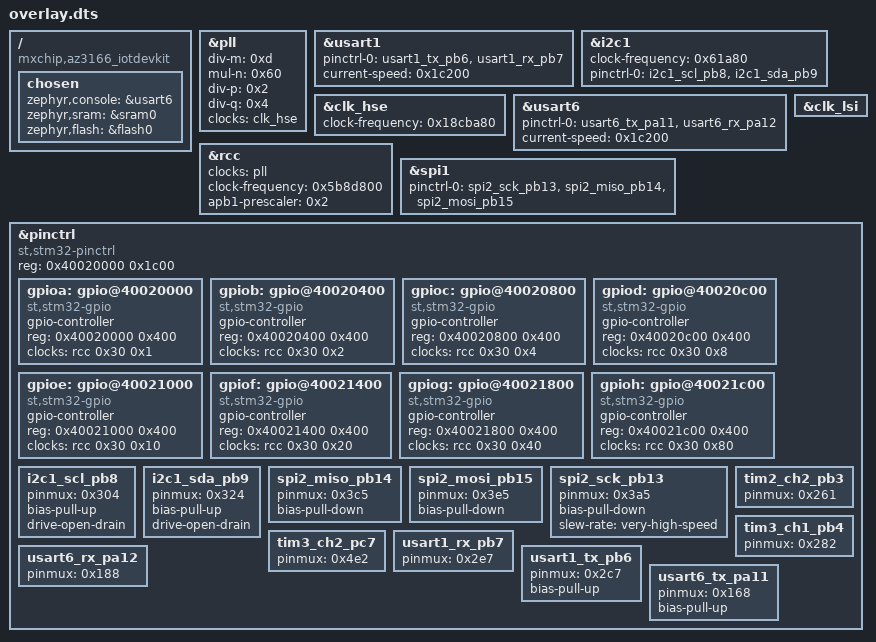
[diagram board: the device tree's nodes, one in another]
/ {
	compatible = "mxchip,az3166_iotdevkit";
	chosen {
		zephyr,console = &usart6;
		zephyr,sram = &sram0;
		zephyr,flash = &flash0;
	};
};
&pll{
	status = "okay";
	div-m = < 0xd >;
	mul-n = < 0x60 >;
	div-p = < 0x2 >;
	div-q = < 0x4 >;
	clocks = < &clk_hse >;
};
&usart1{
	status = "okay";
	pinctrl-0 = < &usart1_tx_pb6 &usart1_rx_pb7 >;
	pinctrl-names = "default";
	current-speed = < 0x1c200 >;
};
&i2c1{
	clock-frequency = < 0x61a80 >;
	status = "okay";
	pinctrl-0 = < &i2c1_scl_pb8 &i2c1_sda_pb9 >;
	pinctrl-names = "default";
};
&clk_hse{
	status = "okay";
	clock-frequency = < 0x18cba80 >;
};
&usart6{
	status = "okay";
	pinctrl-0 = < &usart6_tx_pa11 &usart6_rx_pa12 >;
	pinctrl-names = "default";
	current-speed = < 0x1c200 >;
};
&rcc{
	clocks = < &pll >;
	clock-frequency = < 0x5b8d800 >;
	apb1-prescaler = < 0x2 >;
};
&clk_lsi{
	status = "okay";
};
&spi1{
	status = "okay";
	pinctrl-0 = < &spi2_sck_pb13 &spi2_miso_pb14 &spi2_mosi_pb15 >;
	pinctrl-names = "default";
};
&pinctrl{
	compatible = "st,stm32-pinctrl";
	#address-cells = < 0x1 >;
	#size-cells = < 0x1 >;
	reg = < 0x40020000 0x1c00 >;
	gpioa: gpio@40020000 {
		compatible = "st,stm32-gpio";
		gpio-controller;
		#gpio-cells = < 0x2 >;
		reg = < 0x40020000 0x400 >;
		clocks = < &rcc 0x30 0x1 >;
	};
	gpiob: gpio@40020400 {
		compatible = "st,stm32-gpio";
		gpio-controller;
		#gpio-cells = < 0x2 >;
		reg = < 0x40020400 0x400 >;
		clocks = < &rcc 0x30 0x2 >;
	};
	gpioc: gpio@40020800 {
		compatible = "st,stm32-gpio";
		gpio-controller;
		#gpio-cells = < 0x2 >;
		reg = < 0x40020800 0x400 >;
		clocks = < &rcc 0x30 0x4 >;
	};
	gpiod: gpio@40020c00 {
		compatible = "st,stm32-gpio";
		gpio-controller;
		#gpio-cells = < 0x2 >;
		reg = < 0x40020c00 0x400 >;
		clocks = < &rcc 0x30 0x8 >;
	};
	gpioe: gpio@40021000 {
		compatible = "st,stm32-gpio";
		gpio-controller;
		#gpio-cells = < 0x2 >;
		reg = < 0x40021000 0x400 >;
		clocks = < &rcc 0x30 0x10 >;
	};
	gpiof: gpio@40021400 {
		compatible = "st,stm32-gpio";
		gpio-controller;
		#gpio-cells = < 0x2 >;
		reg = < 0x40021400 0x400 >;
		clocks = < &rcc 0x30 0x20 >;
	};
	gpiog: gpio@40021800 {
		compatible = "st,stm32-gpio";
		gpio-controller;
		#gpio-cells = < 0x2 >;
		reg = < 0x40021800 0x400 >;
		clocks = < &rcc 0x30 0x40 >;
	};
	gpioh: gpio@40021c00 {
		compatible = "st,stm32-gpio";
		gpio-controller;
		#gpio-cells = < 0x2 >;
		reg = < 0x40021c00 0x400 >;
		clocks = < &rcc 0x30 0x80 >;
	};
	i2c1_scl_pb8: i2c1_scl_pb8 {
		pinmux = < 0x304 >;
		bias-pull-up;
		drive-open-drain;
	};
	i2c1_sda_pb9: i2c1_sda_pb9 {
		pinmux = < 0x324 >;
		bias-pull-up;
		drive-open-drain;
	};
	spi2_miso_pb14: spi2_miso_pb14 {
		pinmux = < 0x3c5 >;
		bias-pull-down;
	};
	spi2_mosi_pb15: spi2_mosi_pb15 {
		pinmux = < 0x3e5 >;
		bias-pull-down;
	};
	spi2_sck_pb13: spi2_sck_pb13 {
		pinmux = < 0x3a5 >;
		bias-pull-down;
		slew-rate = "very-high-speed";
	};
	tim2_ch2_pb3: tim2_ch2_pb3 {
		pinmux = < 0x261 >;
	};
	tim3_ch1_pb4: tim3_ch1_pb4 {
		pinmux = < 0x282 >;
	};
	tim3_ch2_pc7: tim3_ch2_pc7 {
		pinmux = < 0x4e2 >;
	};
	usart1_rx_pb7: usart1_rx_pb7 {
		pinmux = < 0x2e7 >;
	};
	usart6_rx_pa12: usart6_rx_pa12 {
		pinmux = < 0x188 >;
	};
	usart1_tx_pb6: usart1_tx_pb6 {
		pinmux = < 0x2c7 >;
		bias-pull-up;
	};
	usart6_tx_pa11: usart6_tx_pa11 {
		pinmux = < 0x168 >;
		bias-pull-up;
	};
};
